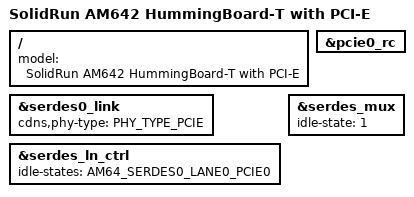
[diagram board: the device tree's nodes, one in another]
// SPDX-License-Identifier: GPL-2.0+
/*
 * Copyright (C) 2023 Josua Mayer <josua@solid-run.com>
 *
 * DTS for SolidRun AM642 HummingBoard-T,
 * running on Cortex A53, with PCI-E.
 *
 */

#include "k3-am642-hummingboard-t.dts"
#include "k3-serdes.h"

/ {
	model = "SolidRun AM642 HummingBoard-T with PCI-E";
};

&pcie0_rc {
	status = "okay";
};

&serdes0_link {
	cdns,phy-type = <PHY_TYPE_PCIE>;
};

&serdes_ln_ctrl {
	idle-states = <AM64_SERDES0_LANE0_PCIE0>;
};

&serdes_mux {
	idle-state = <1>;
};
